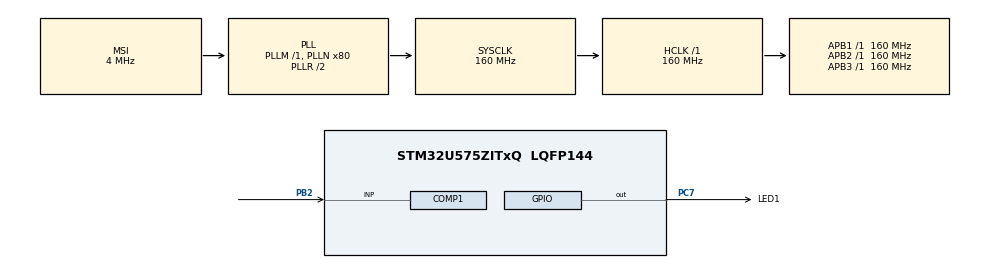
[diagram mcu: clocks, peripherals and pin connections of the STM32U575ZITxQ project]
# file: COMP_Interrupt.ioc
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COMP1.TriggerMode=COMP_TRIGGERMODE_IT_RISING
CORTEX_M33_NS.userName=CORTEX_M33
Mcu.Family=STM32U5
Mcu.Name=STM32U575ZITxQ
Mcu.Package=LQFP144
NVIC.COMP_IRQn=true\:3\:0\:true\:false\:true\:false\:true\:true
NVIC.PriorityGroup=NVIC_PRIORITYGROUP_4
PB2.Mode=INP
PB2.Signal=COMP1_INP
PC7.GPIO_Label=LED1
PC7.Signal=GPIO_Output
PWR.PowerMode=PWR_SMPS_SUPPLY
ProjectManager.HeapSize=0x200
ProjectManager.StackSize=0x400
ProjectManager.TargetToolchain=EWARM V8.50
RCC.ADCFreq_Value=16000000
RCC.AHBFreq_Value=160000000
RCC.APB1Freq_Value=160000000
RCC.APB1TimFreq_Value=160000000
RCC.APB2Freq_Value=160000000
RCC.APB2TimFreq_Value=160000000
RCC.APB3Freq_Value=160000000
RCC.CortexFreq_Value=160000000
RCC.DACCLockSelectionVirtual=RCC_DAC1CLKSOURCE_LSI
RCC.DACCLockSelectionVirtualString=RCC_DAC1CLKSOURCE_LSI
RCC.EPOD_VALUE=4000000
RCC.HCLKFreq_Value=160000000
RCC.HSE_VALUE=16000000
RCC.HSI48_VALUE=48000000
RCC.HSI_VALUE=16000000
RCC.LSE_VALUE=32768
RCC.LSIDIV_VALUE=32000
RCC.MSI_VALUE=4000000
RCC.PLLN=80
RCC.SYSCLKFreq_VALUE=160000000
RCC.SYSCLKSource=RCC_SYSCLKSOURCE_PLLCLK
RCC.USBFreq_Value=48000000
RCC.VCOOutputFreq_Value=320000000
VP_COMP1_VS_VREFINT.Mode=VREFINT
VP_ICACHE_VS_ICACHE.Mode=DirectMappedCache
VP_LPBAMQUEUE_VS_QUEUE.Mode=QUEUEMODE
VP_LPBAM_VS_SIG1.Mode=SmartRun
VP_LPBAM_VS_SIG4.Mode=LPDMA1
VP_PWR_VS_DBSignals.Mode=DisableDeadBatterySignals
VP_PWR_VS_LPOM.Mode=PowerOptimisation
VP_PWR_VS_SECSignals.Mode=Security/Privilege
board=custom

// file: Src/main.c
/* USER CODE BEGIN Header */
/**
  ******************************************************************************
  * @file    COMP/COMP_Interrupt/Src/main.c
  * @author  MCD Application Team
  * @brief   This example provides a short description of how to use the COMP
  *          peripheral Interrupt.
  ******************************************************************************
  * @attention
  *
  * Copyright (c) 2021 STMicroelectronics.
  * All rights reserved.
  *
  * This software is licensed under terms that can be found in the LICENSE file
  * in the root directory of this software component.
  * If no LICENSE file comes with this software, it is provided AS-IS.
  *
  ******************************************************************************
  */
/* USER CODE END Header */
#include "main.h"

COMP_HandleTypeDef hcomp1;

void SystemClock_Config(void);
static void SystemPower_Config(void);
static void MX_GPIO_Init(void);
static void MX_ICACHE_Init(void);
static void MX_COMP1_Init(void);
/* USER CODE BEGIN PFP */
void SystemClock_Restore(void);
/* USER CODE END PFP */

int main(void)
{

  /* USER CODE BEGIN 1 */
  /* STM32U5xx HAL library initialization:
       - Configure the Flash prefetch
       - Configure the Systick to generate an interrupt each 1 msec
       - Set NVIC Group Priority to 3
       - Low Level Initialization
     */
  /* USER CODE END 1 */

  /* MCU Configuration--------------------------------------------------------*/

  /* Reset of all peripherals, Initializes the Flash interface and the Systick. */
  HAL_Init();

  /* Configure the System Power */
  SystemPower_Config();

  /* Configure the system clock */
  SystemClock_Config();

  /* USER CODE BEGIN SysInit */
  /* Initialize LED1*/
  BSP_LED_Init(LED1);

  /* LED1 off */
  BSP_LED_Off(LED1);
  /* USER CODE END SysInit */

  /* Initialize all configured peripherals */
  MX_GPIO_Init();
  MX_ICACHE_Init();
  MX_COMP1_Init();
  /* USER CODE BEGIN 2 */
  /* Start COMP1 */
  if(HAL_COMP_Start(&hcomp1) != HAL_OK)
  {
    /* Initialization Error */
    Error_Handler();
  }
  /* USER CODE END 2 */

  /* Infinite loop */
  while (1)
  {

    /* USER CODE BEGIN 3 */
    /* Insert 5 second delay */
    HAL_Delay(5000);

    /* Toggle LED1 4 times before entering in low-power mode */
    BSP_LED_Toggle(LED1);
    HAL_Delay(100);
    BSP_LED_Toggle(LED1);
    HAL_Delay(100);
    BSP_LED_Toggle(LED1);
    HAL_Delay(100);
    BSP_LED_Toggle(LED1);
    HAL_Delay(100);

    /* PWR clock enable */
    __HAL_RCC_PWR_CLK_ENABLE();

    /* Enter the system to stop 2 mode */
    HAL_PWREx_EnterSTOP2Mode(PWR_STOPENTRY_WFI);

    /* Check that the system was resumed from stop 2 */
    if(__HAL_PWR_GET_FLAG(PWR_FLAG_STOPF) == 0U)
    {
      /* Initialization Error */
      Error_Handler();
    }

    /* Clear stop flag */
    __HAL_PWR_CLEAR_FLAG(PWR_FLAG_STOPF);

    /* Check that stop flag is cleared */
    if (__HAL_PWR_GET_FLAG(PWR_FLAG_STOPF) != 0U)
    {
      /* Initialization Error */
      Error_Handler();
    }

    /* Re-configure the system clock to 160 MHz, enable and
    select PLL as system clock source (PLL is disabled in STOP mode) */
    SystemClock_Restore();
  }
  /* USER CODE END 3 */
}

void SystemClock_Config(void)
{
  RCC_OscInitTypeDef RCC_OscInitStruct = {0};
  RCC_ClkInitTypeDef RCC_ClkInitStruct = {0};

  /** Configure the main internal regulator output voltage
  */
  if (HAL_PWREx_ControlVoltageScaling(PWR_REGULATOR_VOLTAGE_SCALE1) != HAL_OK)
  {
    Error_Handler();
  }

  /** Initializes the CPU, AHB and APB buses clocks
  */
  RCC_OscInitStruct.OscillatorType = RCC_OSCILLATORTYPE_MSI;
  RCC_OscInitStruct.MSIState = RCC_MSI_ON;
  RCC_OscInitStruct.MSICalibrationValue = RCC_MSICALIBRATION_DEFAULT;
  RCC_OscInitStruct.MSIClockRange = RCC_MSIRANGE_4;
  RCC_OscInitStruct.PLL.PLLState = RCC_PLL_ON;
  RCC_OscInitStruct.PLL.PLLSource = RCC_PLLSOURCE_MSI;
  RCC_OscInitStruct.PLL.PLLMBOOST = RCC_PLLMBOOST_DIV1;
  RCC_OscInitStruct.PLL.PLLM = 1;
  RCC_OscInitStruct.PLL.PLLN = 80;
  RCC_OscInitStruct.PLL.PLLP = 2;
  RCC_OscInitStruct.PLL.PLLQ = 2;
  RCC_OscInitStruct.PLL.PLLR = 2;
  RCC_OscInitStruct.PLL.PLLRGE = RCC_PLLVCIRANGE_0;
  RCC_OscInitStruct.PLL.PLLFRACN = 0;
  if (HAL_RCC_OscConfig(&RCC_OscInitStruct) != HAL_OK)
  {
    Error_Handler();
  }

  /** Initializes the CPU, AHB and APB buses clocks
  */
  RCC_ClkInitStruct.ClockType = RCC_CLOCKTYPE_HCLK|RCC_CLOCKTYPE_SYSCLK
                              |RCC_CLOCKTYPE_PCLK1|RCC_CLOCKTYPE_PCLK2
                              |RCC_CLOCKTYPE_PCLK3;
  RCC_ClkInitStruct.SYSCLKSource = RCC_SYSCLKSOURCE_PLLCLK;
  RCC_ClkInitStruct.AHBCLKDivider = RCC_SYSCLK_DIV1;
  RCC_ClkInitStruct.APB1CLKDivider = RCC_HCLK_DIV1;
  RCC_ClkInitStruct.APB2CLKDivider = RCC_HCLK_DIV1;
  RCC_ClkInitStruct.APB3CLKDivider = RCC_HCLK_DIV1;

  if (HAL_RCC_ClockConfig(&RCC_ClkInitStruct, FLASH_LATENCY_4) != HAL_OK)
  {
    Error_Handler();
  }
}

/**
  * @brief Power Configuration
  * @retval None
  */
static void SystemPower_Config(void)
{

  /*
   * Disable the internal Pull-Up in Dead Battery pins of UCPD peripheral
   */
  HAL_PWREx_DisableUCPDDeadBattery();

  /*
   * Switch to SMPS regulator instead of LDO
   */
  if (HAL_PWREx_ConfigSupply(PWR_SMPS_SUPPLY) != HAL_OK)
  {
    Error_Handler();
  }
}

static void MX_COMP1_Init(void)
{

  hcomp1.Instance = COMP1;
  hcomp1.Init.InputPlus = COMP_INPUT_PLUS_IO2;
  hcomp1.Init.InputMinus = COMP_INPUT_MINUS_VREFINT;
  hcomp1.Init.OutputPol = COMP_OUTPUTPOL_NONINVERTED;
  hcomp1.Init.WindowOutput = COMP_WINDOWOUTPUT_EACH_COMP;
  hcomp1.Init.Hysteresis = COMP_HYSTERESIS_NONE;
  hcomp1.Init.BlankingSrce = COMP_BLANKINGSRC_NONE;
  hcomp1.Init.Mode = COMP_POWERMODE_HIGHSPEED;
  hcomp1.Init.WindowMode = COMP_WINDOWMODE_DISABLE;
  hcomp1.Init.TriggerMode = COMP_TRIGGERMODE_IT_RISING;
  if (HAL_COMP_Init(&hcomp1) != HAL_OK)
  {
    Error_Handler();
  }

}

static void MX_ICACHE_Init(void)
{

  /** Enable instruction cache in 1-way (direct mapped cache)
  */
  if (HAL_ICACHE_ConfigAssociativityMode(ICACHE_1WAY) != HAL_OK)
  {
    Error_Handler();
  }
  if (HAL_ICACHE_Enable() != HAL_OK)
  {
    Error_Handler();
  }

}

static void MX_GPIO_Init(void)
{
  GPIO_InitTypeDef GPIO_InitStruct = {0};

  /* GPIO Ports Clock Enable */
  __HAL_RCC_GPIOB_CLK_ENABLE();
  __HAL_RCC_GPIOC_CLK_ENABLE();

  /*Configure GPIO pin Output Level */
  HAL_GPIO_WritePin(LED1_GPIO_Port, LED1_Pin, GPIO_PIN_RESET);

  /*Configure GPIO pin : LED1_Pin */
  GPIO_InitStruct.Pin = LED1_Pin;
  GPIO_InitStruct.Mode = GPIO_MODE_OUTPUT_PP;
  GPIO_InitStruct.Pull = GPIO_NOPULL;
  GPIO_InitStruct.Speed = GPIO_SPEED_FREQ_LOW;
  HAL_GPIO_Init(LED1_GPIO_Port, &GPIO_InitStruct);

}

/* USER CODE BEGIN 4 */
/**
  * @brief  Restore system clock after wake-up from STOP: enable MSI, PLL
  *         and select PLL as system clock source.
  * @param  None
  * @retval None
  */
void SystemClock_Restore(void)
{
  RCC_ClkInitTypeDef RCC_ClkInitStruct;
  RCC_OscInitTypeDef RCC_OscInitStruct;
  uint32_t pFLatency;

  /* The voltage scaling allows optimizing the power consumption when the device is
  clocked below the maximum system frequency, to update the voltage scaling value
  regarding system frequency refer to product datasheet.
  */
  __HAL_PWR_VOLTAGESCALING_CONFIG(PWR_REGULATOR_VOLTAGE_SCALE1);

  while(!__HAL_PWR_GET_FLAG(PWR_FLAG_VOSRDY)) {}
  /* Get the Oscillators and PLL configuration according to the internal RCC registers */
  HAL_RCC_GetOscConfig(&RCC_OscInitStruct);

  /* After wake-up from STOP reconfigure the system clock: Enable PLL */
  RCC_OscInitStruct.OscillatorType  = RCC_OSCILLATORTYPE_NONE;
  RCC_OscInitStruct.PLL.PLLState    = RCC_PLL_ON;
  if (HAL_RCC_OscConfig(&RCC_OscInitStruct) != HAL_OK)
  {
    while(1);
  }

  /* Get the Clocks configuration according to the internal RCC registers */
  HAL_RCC_GetClockConfig(&RCC_ClkInitStruct, &pFLatency);

  /* Select PLL as system clock source with previous HCLK, PCLK1 and PCLK2
  clocks dividers */
  RCC_ClkInitStruct.ClockType     = RCC_CLOCKTYPE_SYSCLK;
  RCC_ClkInitStruct.SYSCLKSource  = RCC_SYSCLKSOURCE_PLLCLK;
  if (HAL_RCC_ClockConfig(&RCC_ClkInitStruct, pFLatency) != HAL_OK)
  {
    while(1);
  }
}
/* USER CODE END 4 */

void Error_Handler(void)
{
  /* USER CODE BEGIN Error_Handler_Debug */
  /* User can add his own implementation to report the HAL error return state */
  __disable_irq();
  while (1)
  {
    /* Toggle LED1 */
    BSP_LED_Toggle(LED1);

    /* Add a delay */
    HAL_Delay(100);
  }
  /* USER CODE END Error_Handler_Debug */
}
